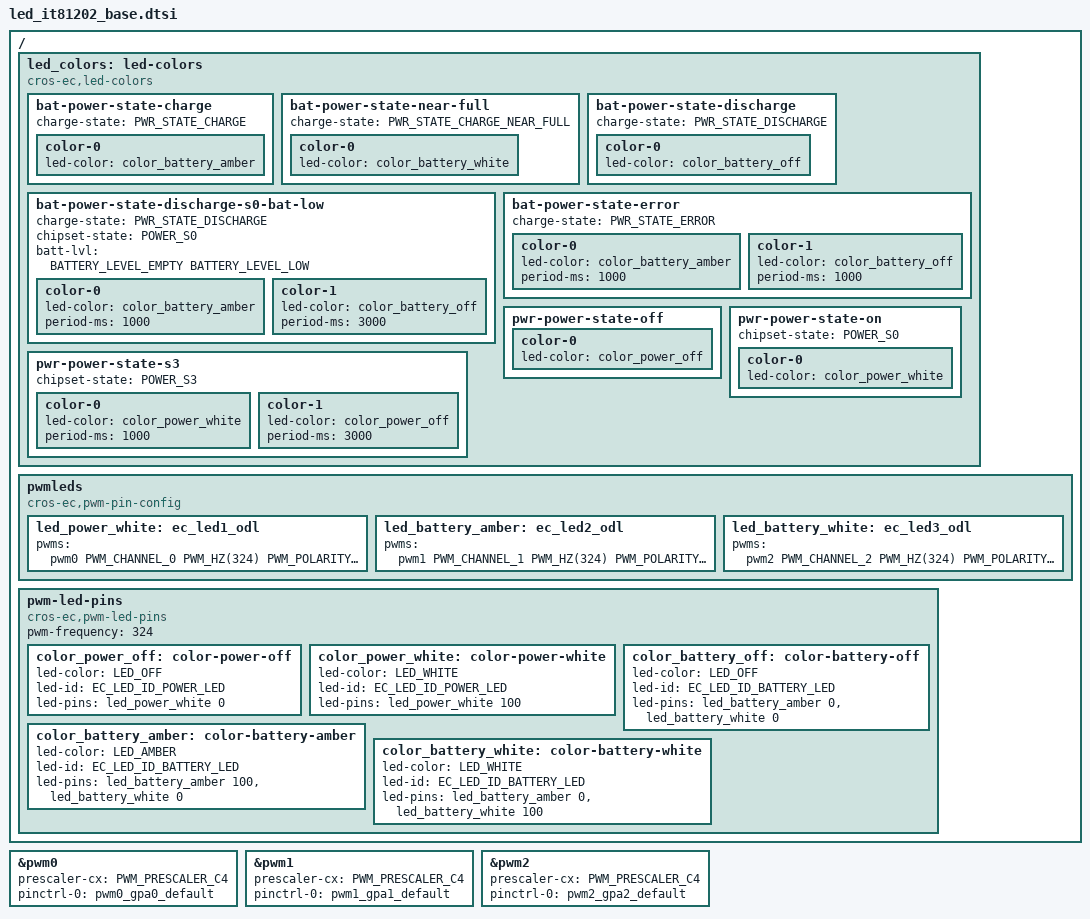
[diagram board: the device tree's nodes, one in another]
/* Copyright 2022 The ChromiumOS Authors.
 * Use of this source code is governed by a BSD-style license that can be
 * found in the LICENSE file.
 */
#include <dt-bindings/battery.h>

/ {
	led_colors: led-colors {
		compatible = "cros-ec,led-colors";

		bat-power-state-charge {
			charge-state = "PWR_STATE_CHARGE";

			color-0 {
				led-color = <&color_battery_amber>;
			};
		};

		bat-power-state-near-full {
			charge-state = "PWR_STATE_CHARGE_NEAR_FULL";

			color-0 {
				led-color = <&color_battery_white>;
			};
		};

		bat-power-state-discharge {
			charge-state = "PWR_STATE_DISCHARGE";

			color-0 {
				led-color = <&color_battery_off>;
			};
		};

		bat-power-state-discharge-s0-bat-low {
			charge-state = "PWR_STATE_DISCHARGE";
			chipset-state = "POWER_S0";
			batt-lvl = <BATTERY_LEVEL_EMPTY BATTERY_LEVEL_LOW>;

			color-0 {
				led-color = <&color_battery_amber>;
				period-ms = <1000>;
			};

			color-1 {
				led-color = <&color_battery_off>;
				period-ms = <3000>;
			};
		};

		bat-power-state-error {
			charge-state = "PWR_STATE_ERROR";

			color-0 {
				led-color = <&color_battery_amber>;
				period-ms = <1000>;
			};

			color-1 {
				led-color = <&color_battery_off>;
				period-ms = <1000>;
			};
		};

		pwr-power-state-off {
			color-0 {
				led-color = <&color_power_off>;
			};
		};

		pwr-power-state-on {
			chipset-state = "POWER_S0";

			color-0 {
				led-color = <&color_power_white>;
			};
		};

		pwr-power-state-s3 {
			chipset-state = "POWER_S3";

			color-0 {
				led-color = <&color_power_white>;
				period-ms = <1000>;
			};

			color-1 {
				led-color = <&color_power_off>;
				period-ms = <3000>;
			};
		};
	};

	pwmleds {
		compatible = "cros-ec,pwm-pin-config";

		/* NOTE: &pwm number needs same with channel number */
		led_power_white: ec_led1_odl {
			#led-pin-cells = <1>;
			pwms = <&pwm0
				PWM_CHANNEL_0
				PWM_HZ(324)
				PWM_POLARITY_INVERTED>;
		};
		led_battery_amber: ec_led2_odl {
			#led-pin-cells = <1>;
			pwms = <&pwm1
				PWM_CHANNEL_1
				PWM_HZ(324)
				PWM_POLARITY_INVERTED>;
		};
		led_battery_white: ec_led3_odl {
			#led-pin-cells = <1>;
			pwms = <&pwm2
				PWM_CHANNEL_2
				PWM_HZ(324)
				PWM_POLARITY_INVERTED>;
		};
	};

	pwm-led-pins {
		compatible = "cros-ec,pwm-led-pins";
		pwm-frequency = <324>;

		color_power_off: color-power-off {
			led-color = "LED_OFF";
			led-id = "EC_LED_ID_POWER_LED";
			led-pins = <&led_power_white 0>;
		};

		color_power_white: color-power-white {
			led-color = "LED_WHITE";
			led-id = "EC_LED_ID_POWER_LED";
			led-pins = <&led_power_white 100>;
		};

		color_battery_off: color-battery-off {
			led-color = "LED_OFF";
			led-id = "EC_LED_ID_BATTERY_LED";
			led-pins = <&led_battery_amber 0>,
				   <&led_battery_white 0>;
		};

		color_battery_amber: color-battery-amber {
			led-color = "LED_AMBER";
			led-id = "EC_LED_ID_BATTERY_LED";
			led-pins = <&led_battery_amber 100>,
				   <&led_battery_white 0>;
		};

		color_battery_white: color-battery-white {
			led-color = "LED_WHITE";
			led-id = "EC_LED_ID_BATTERY_LED";
			led-pins = <&led_battery_amber 0>,
				   <&led_battery_white 100>;
		};
	};
};

/* LED1 */
&pwm0 {
	status = "okay";
	prescaler-cx = <PWM_PRESCALER_C4>;
	pinctrl-0 = <&pwm0_gpa0_default>;
	pinctrl-names = "default";
};

/* LED2 */
&pwm1 {
	status = "okay";
	prescaler-cx = <PWM_PRESCALER_C4>;
	pinctrl-0 = <&pwm1_gpa1_default>;
	pinctrl-names = "default";
};

/* LED3 */
&pwm2 {
	status = "okay";
	prescaler-cx = <PWM_PRESCALER_C4>;
	pinctrl-0 = <&pwm2_gpa2_default>;
	pinctrl-names = "default";
};
